AUTOSAR XML (schema 00045)
package /FctAdapter
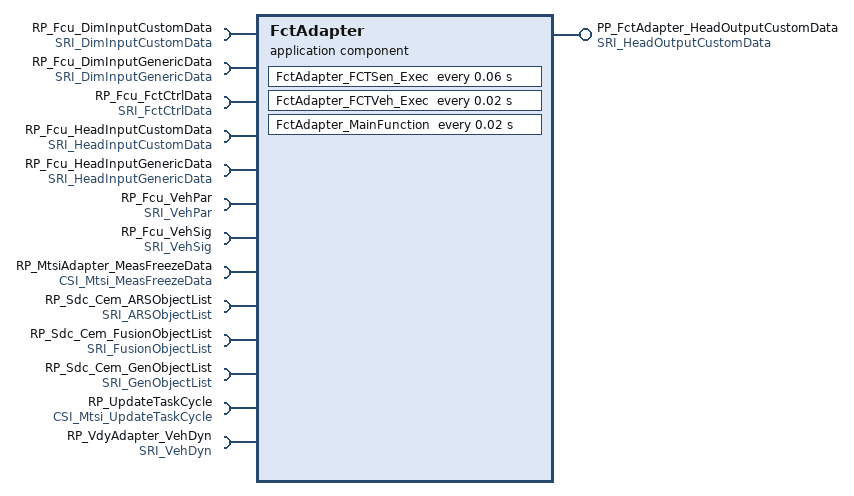
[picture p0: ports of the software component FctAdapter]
  application sw component type FctAdapter  # Algo of ACC and AEB adapter
    provide port PP_FctAdapter_HeadOutputCustomData: provided-interface=SRI_HeadOutputCustomData
    13 x require port:
      RP_Fcu_DimInputCustomData: required-interface=SRI_DimInputCustomData
      RP_Fcu_DimInputGenericData: required-interface=SRI_DimInputGenericData
      RP_Fcu_FctCtrlData: required-interface=SRI_FctCtrlData
      RP_Fcu_HeadInputCustomData: required-interface=SRI_HeadInputCustomData
      RP_Fcu_HeadInputGenericData: required-interface=SRI_HeadInputGenericData
      RP_Fcu_VehPar: required-interface=SRI_VehPar
      RP_Fcu_VehSig: required-interface=SRI_VehSig
      RP_MtsiAdapter_MeasFreezeData: required-interface=CSI_Mtsi_MeasFreezeData
      RP_Sdc_Cem_ARSObjectList: required-interface=SRI_ARSObjectList
      RP_Sdc_Cem_FusionObjectList: required-interface=SRI_FusionObjectList
      RP_Sdc_Cem_GenObjectList: required-interface=SRI_GenObjectList
      RP_UpdateTaskCycle: required-interface=CSI_Mtsi_UpdateTaskCycle
      RP_VdyAdapter_VehDyn: required-interface=SRI_VehDyn
    behavior FctAdapter_IB: handle-termination-and-restart=NO-SUPPORT
      init event InitEvent_FctAdapter_InitFunction: start-on-event=FctAdapter_InitFunction
      timing event TimingEvent_FctAdapter_FCTSen_Exec: start-on-event=FctAdapter_FCTSen_Exec, period=0.06
      timing event TimingEvent_FctAdapter_FctVeh_Exec: start-on-event=FctAdapter_FCTVeh_Exec, period=0.02
      timing event TimingEvent_FctAdapter_MainFunction: start-on-event=FctAdapter_MainFunction, period=0.02
      4 x runnable:
        FctAdapter_FCTSen_Exec
        FctAdapter_FCTVeh_Exec
        FctAdapter_InitFunction
        FctAdapter_MainFunction
          data-receive-point-by-arguments:
            11 x access:
              drparg_ARSObjectList: accessed-variable=RP_Sdc_Cem_ARSObjectList.ARSObjectList
              drparg_DimInputCustomData: accessed-variable=RP_Fcu_DimInputCustomData.DimInputCustomData
              drparg_DimInputGenericData: accessed-variable=RP_Fcu_DimInputGenericData.DimInputGenericData
              drparg_FctCtrlData: accessed-variable=RP_Fcu_FctCtrlData.FctCtrlData
              drparg_FusionObjectList: accessed-variable=RP_Sdc_Cem_FusionObjectList.FusionObjectList
              drparg_GenObjectList: accessed-variable=RP_Sdc_Cem_GenObjectList.GenObjectList
              drparg_HeadInputCustomData: accessed-variable=RP_Fcu_HeadInputCustomData.HeadInputCustomData
              drparg_HeadInputGenericData: accessed-variable=RP_Fcu_HeadInputGenericData.HeadInputGenericData
              drparg_VehDyn: accessed-variable=RP_VdyAdapter_VehDyn.VehDyn
              drparg_VehPar0: accessed-variable=RP_Fcu_VehPar.VehPar
              drparg_VehSig: accessed-variable=RP_Fcu_VehSig.VehSig
          data-send-points:
            access dsp_HeadOutputCustomData: accessed-variable=PP_FctAdapter_HeadOutputCustomData.HeadOutputCustomData
          sync call scp_MeasFreezeData: operation=RP_MtsiAdapter_MeasFreezeData.MeasFreezeData, timeout=0.0
          sync call scp_UpdateTaskCycle: operation=RP_UpdateTaskCycle.UpdateTaskCycle, timeout=0.0
  swc implementation FctAdapterImpl: programming-language=C, sw-version=1.0.0, vendor-id=0, behavior=FctAdapter_IB
    code-descriptors:
      code CodeGen: artifact-descriptors=[{short-label=SWHDR, category=SWHDR}, {short-label=SWSRC, category=SWSRC}]
    resource consumption Resource
      memory section CODE: sw-addrmethod=CODE
      memory section VAR_UNSPECIFIED: sw-addrmethod=VAR
